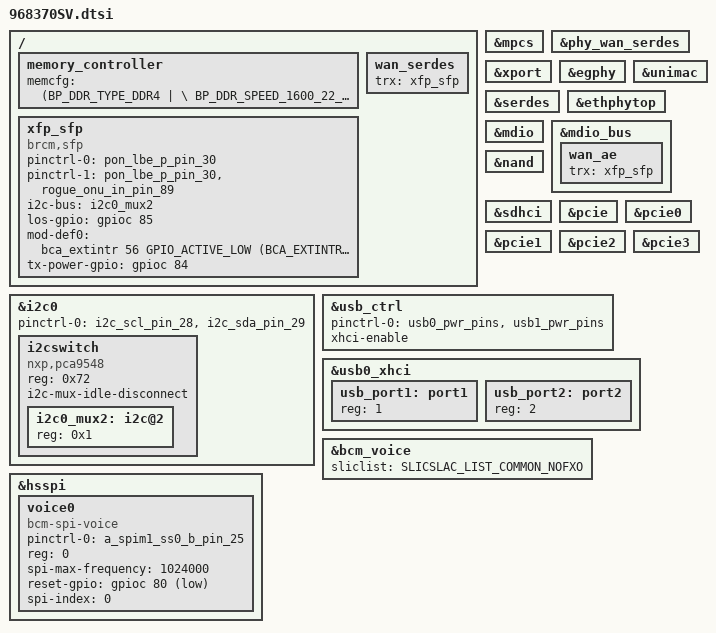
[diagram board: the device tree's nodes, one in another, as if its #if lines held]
#include "68370.dtsi"
#include "../../bcm_voice.dtsi"

/ {
	memory_controller {
		memcfg = <(BP_DDR_TYPE_DDR4        | \
				BP_DDR_SPEED_1600_22_22_22 | \
				BP_DDR_DEVICE_WIDTH_16     | \
				BP_DDR_TOTAL_WIDTH_32BIT   | \
				BP_DDR_TOTAL_SIZE_2048MB   | \
				BP_DDR_SSC_CONFIG_1        | \
				BP_DDR_CONFIG_DEBUG)>;
	};
};

/ {
    xfp_sfp: xfp_sfp {
        pinctrl-names = "default", "tx-sd";
        pinctrl-0 = <&pon_lbe_p_pin_30>;
        pinctrl-1 = <&pon_lbe_p_pin_30 &rogue_onu_in_pin_89>;
        compatible = "brcm,sfp";
        i2c-bus = <&i2c0_mux2>;
        los-gpio = <&gpioc 85 GPIO_ACTIVE_HIGH>;
        mod-def0 = <&bca_extintr 56 GPIO_ACTIVE_LOW (BCA_EXTINTR_TYPE_BOTH_EDGE | BCA_EXTINTR_TYPE_SENSE_EDGE)>;
        tx-power-gpio = <&gpioc 84 GPIO_ACTIVE_HIGH>;
    };

    wan_serdes {
        status = "okay";
        trx = <&xfp_sfp>;
    };
};

&i2c0 {
    pinctrl-0 = <&i2c_scl_pin_28 &i2c_sda_pin_29>;
    pinctrl-names = "default";
    status = "okay";

    i2cswitch {
        compatible = "nxp,pca9548";
        #address-cells = <1>;
        #size-cells = <0>;
        reg = <0x72>;
        i2c-mux-idle-disconnect;

        i2c0_mux2: i2c@2 {
            reg = <0x1>;
        };
    };
};

&mpcs {
    status = "okay";
};

&phy_wan_serdes {
    status = "okay";
};

&xport {
    status = "okay";
};

&egphy {
    status = "okay";
};

&unimac {
    status = "okay";
};

&serdes {
    status = "okay";
};

&ethphytop {
    status = "okay";
};

&mdio {
    status = "okay";
};

&mdio_bus {
    wan_ae {
        trx = <&xfp_sfp>;
        status = "okay";
    };
};

#ifndef CONFIG_BRCM_SMC_BOOT
&nand {
    status = "okay";
};
&sdhci {
    status = "okay";
};
#endif

#if defined(CONFIG_BCM_PCIE_HCD) || defined(CONFIG_BCM_PCIE_HCD_MODULE)
&pcie {
        status = "okay";
};
&pcie0 {
        status = "okay";
};
&pcie1 {
        status = "okay";
};
&pcie2 {
        status = "okay";
};
&pcie3 {
        status = "okay";
};
#endif

&usb_ctrl {
	pinctrl-names = "default";
	pinctrl-0 = <&usb0_pwr_pins &usb1_pwr_pins>;
	xhci-enable;
	status = "okay";
};

&usb0_xhci {
	status = "okay";

	usb_port1: port1 {
		reg = <1>;
		#trigger-source-cells = <0>;
	};

	usb_port2: port2 {
		reg = <2>;
		#trigger-source-cells = <0>;
	};
};

&bcm_voice {
        sliclist = SLICSLAC_LIST_COMMON_NOFXO;
};

&hsspi {
        status = "okay";
        voice0 {
                pinctrl-0 = <&a_spim1_ss0_b_pin_25>;
                pinctrl-names = "default";
                compatible = "bcm-spi-voice";
                reg = <0>; 
                spi-max-frequency = <1024000>;
                reset-gpio = <&gpioc 80 GPIO_ACTIVE_LOW>;
                spi-index = <0>;
        };
};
